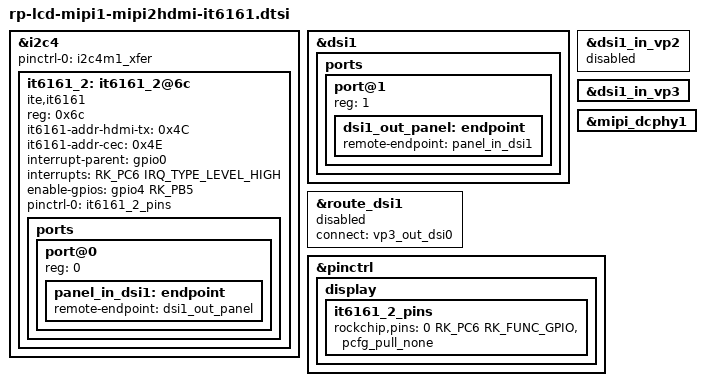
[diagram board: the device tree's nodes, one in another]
&i2c4 {
    status = "okay";
    pinctrl-names = "default";
    pinctrl-0 = <&i2c4m1_xfer>;
    
    /*
    ite6161 max output 1080p@p60
    dsi1->vp2(max 4096x2304@60Hz)->ite6161->card0-HDMI-A-3
    */
    it6161_2: it6161_2@6c {
        status = "okay";
        compatible = "ite,it6161";
        #sound-dai-cells = <0>;
        reg = <0x6c>;
        it6161-addr-hdmi-tx = <0x4C>;
        it6161-addr-cec = <0x4E>;
        interrupt-parent = <&gpio0>;
        interrupts = <RK_PC6 IRQ_TYPE_LEVEL_HIGH>; 
        // interrupts = <RK_PC6 IRQ_TYPE_EDGE_RISING>;
        enable-gpios = <&gpio4 RK_PB5 GPIO_ACTIVE_HIGH>;
        pinctrl-names = "default";
        pinctrl-0 = <&it6161_2_pins>;

        ports {
            #address-cells = <1>;
            #size-cells = <0>;
            port@0 {
                reg = <0>;
                panel_in_dsi1: endpoint {
                    remote-endpoint = <&dsi1_out_panel>;
                };
            };
        };
    }; 
};

&dsi1 {
    status = "okay";
    ports {
        #address-cells = <1>;
        #size-cells = <0>;

        port@1 {
            reg = <1>;
            dsi1_out_panel: endpoint {
                remote-endpoint = <&panel_in_dsi1>;
            };
        };
    };
};


&dsi1_in_vp2 {
    status = "disabled";
};

&dsi1_in_vp3 {
    status = "okay";
};

&mipi_dcphy1 {
    status = "okay";
};

// ite6161 not have uboot driver, don't enable display logo
&route_dsi1 {
    status = "disabled";
    connect = <&vp3_out_dsi0>;
};

&pinctrl {
    display {
        it6161_2_pins: it6161_2_pins {
            rockchip,pins =<0 RK_PC6 RK_FUNC_GPIO &pcfg_pull_none>;
        };
    };
};
